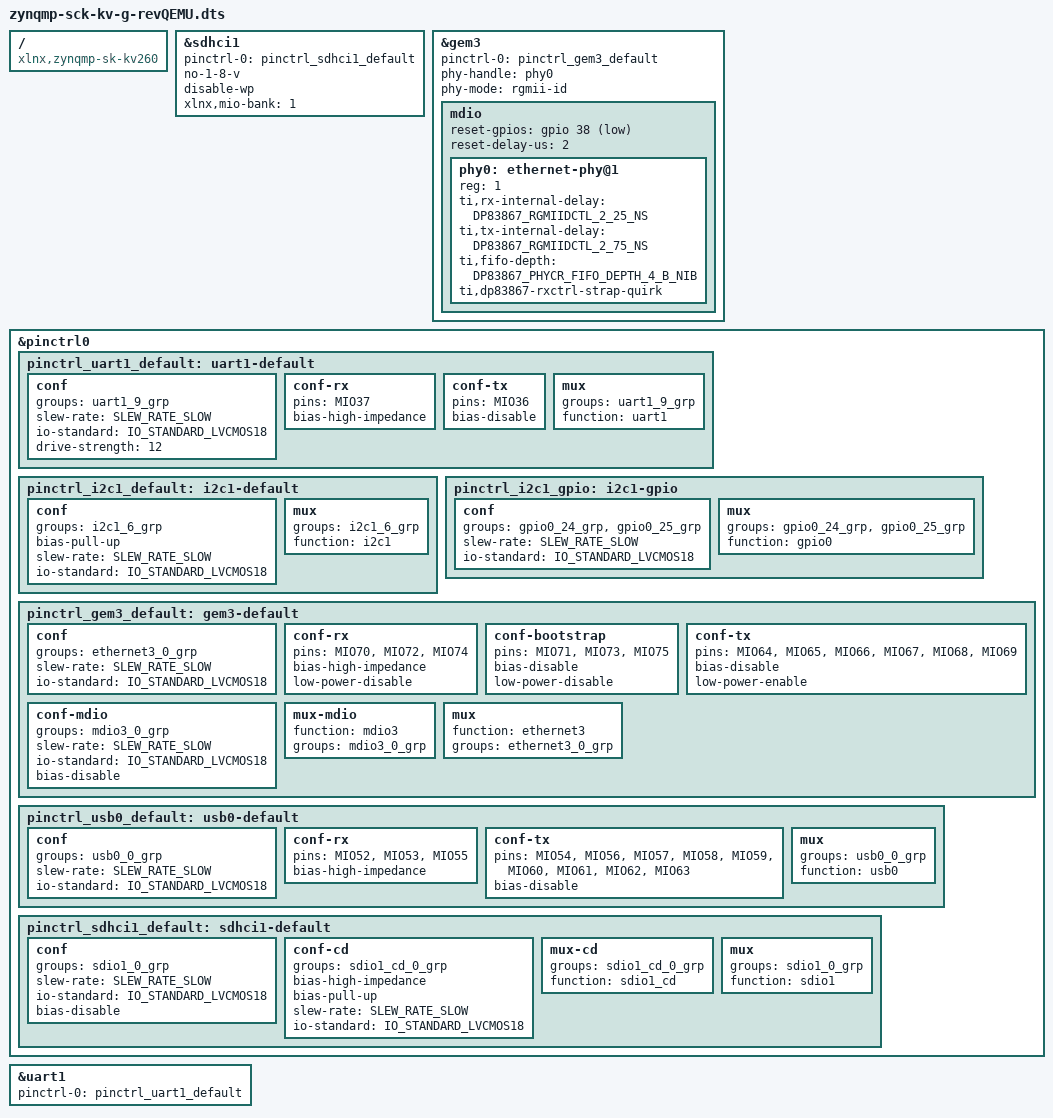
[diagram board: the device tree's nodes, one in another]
// SPDX-License-Identifier: GPL-2.0
/*
 * Carrier dts file for qemu,
 *
 * Reference from zynqmp-sck-kv-g-revA01.dts
 *
 * (C) Copyright 2021, Xilinx, Inc.
 *
 */

 #include <dt-bindings/gpio/gpio.h>
 #include <dt-bindings/net/ti-dp83867.h>
 #include <dt-bindings/phy/phy.h>
 #include <dt-bindings/pinctrl/pinctrl-zynqmp.h>

/dts-v1/;
/plugin/;

/{
	compatible = "xlnx,zynqmp-sk-kv260", "xlnx,zynqmp";

	fragment12 {
		target = <&sdhci1>; /* on CC with tuned parameters */
		__overlay__ {
			status = "okay";
			pinctrl-names = "default";
			pinctrl-0 = <&pinctrl_sdhci1_default>;
			/*
			 * SD 3.0 requires level shifter and this property
			 * should be removed if the board has level shifter and
			 * need to work in UHS mode
			 */
			no-1-8-v;
			disable-wp;
			xlnx,mio-bank = <1>;
		};
	};

	fragment13 {
		target = <&gem3>; /* required by spec */
		__overlay__ {
			#address-cells = <1>;
			#size-cells = <0>;
			status = "okay";
			pinctrl-names = "default";
			pinctrl-0 = <&pinctrl_gem3_default>;
			phy-handle = <&phy0>;
			phy-mode = "rgmii-id";

			mdio: mdio {
				#address-cells = <1>;
				#size-cells = <0>;
				reset-gpios = <&gpio 38 GPIO_ACTIVE_LOW>;
				reset-delay-us = <2>;

				phy0: ethernet-phy@1 {
					#phy-cells = <1>;
					reg = <1>;
					ti,rx-internal-delay = <DP83867_RGMIIDCTL_2_25_NS>;
					ti,tx-internal-delay = <DP83867_RGMIIDCTL_2_75_NS>;
					ti,fifo-depth = <DP83867_PHYCR_FIFO_DEPTH_4_B_NIB>;
					ti,dp83867-rxctrl-strap-quirk;
				};
			};
		};
	};

	fragment14 {
		target = <&pinctrl0>; /* required by spec */
		__overlay__ {
			status = "okay";

			pinctrl_uart1_default: uart1-default {
				conf {
					groups = "uart1_9_grp";
					slew-rate = <SLEW_RATE_SLOW>;
					io-standard = <IO_STANDARD_LVCMOS18>;
					drive-strength = <12>;
				};

				conf-rx {
					pins = "MIO37";
					bias-high-impedance;
				};

				conf-tx {
					pins = "MIO36";
					bias-disable;
				};

				mux {
					groups = "uart1_9_grp";
					function = "uart1";
				};
			};

			pinctrl_i2c1_default: i2c1-default {
				conf {
					groups = "i2c1_6_grp";
					bias-pull-up;
					slew-rate = <SLEW_RATE_SLOW>;
					io-standard = <IO_STANDARD_LVCMOS18>;
				};

				mux {
					groups = "i2c1_6_grp";
					function = "i2c1";
				};
			};

			pinctrl_i2c1_gpio: i2c1-gpio {
				conf {
					groups = "gpio0_24_grp", "gpio0_25_grp";
					slew-rate = <SLEW_RATE_SLOW>;
					io-standard = <IO_STANDARD_LVCMOS18>;
				};

				mux {
					groups = "gpio0_24_grp", "gpio0_25_grp";
					function = "gpio0";
				};
			};

			pinctrl_gem3_default: gem3-default {
				conf {
					groups = "ethernet3_0_grp";
					slew-rate = <SLEW_RATE_SLOW>;
					io-standard = <IO_STANDARD_LVCMOS18>;
				};

				conf-rx {
					pins = "MIO70", "MIO72", "MIO74";
					bias-high-impedance;
					low-power-disable;
				};

				conf-bootstrap {
					pins = "MIO71", "MIO73", "MIO75";
					bias-disable;
					low-power-disable;
				};

				conf-tx {
					pins = "MIO64", "MIO65", "MIO66",
					       "MIO67", "MIO68", "MIO69";
					bias-disable;
					low-power-enable;
				};

				conf-mdio {
					groups = "mdio3_0_grp";
					slew-rate = <SLEW_RATE_SLOW>;
					io-standard = <IO_STANDARD_LVCMOS18>;
					bias-disable;
				};

				mux-mdio {
					function = "mdio3";
					groups = "mdio3_0_grp";
				};

				mux {
					function = "ethernet3";
					groups = "ethernet3_0_grp";
				};
			};

			pinctrl_usb0_default: usb0-default {
				conf {
					groups = "usb0_0_grp";
					slew-rate = <SLEW_RATE_SLOW>;
					io-standard = <IO_STANDARD_LVCMOS18>;
				};

				conf-rx {
					pins = "MIO52", "MIO53", "MIO55";
					bias-high-impedance;
				};

				conf-tx {
					pins = "MIO54", "MIO56", "MIO57", "MIO58", "MIO59",
					"MIO60", "MIO61", "MIO62", "MIO63";
					bias-disable;
				};

				mux {
					groups = "usb0_0_grp";
					function = "usb0";
				};
			};

			pinctrl_sdhci1_default: sdhci1-default {
				conf {
					groups = "sdio1_0_grp";
					slew-rate = <SLEW_RATE_SLOW>;
					io-standard = <IO_STANDARD_LVCMOS18>;
					bias-disable;
				};

				conf-cd {
					groups = "sdio1_cd_0_grp";
					bias-high-impedance;
					bias-pull-up;
					slew-rate = <SLEW_RATE_SLOW>;
					io-standard = <IO_STANDARD_LVCMOS18>;
				};

				mux-cd {
					groups = "sdio1_cd_0_grp";
					function = "sdio1_cd";
				};

				mux {
					groups = "sdio1_0_grp";
					function = "sdio1";
				};
			};
		};
	};
	fragment15 {
		target = <&uart1>;
		__overlay__ {
			status = "okay";
			pinctrl-names = "default";
			pinctrl-0 = <&pinctrl_uart1_default>;
		};
	};
};
